# EFM32G290F128 register map
File version: 4.0.0
CPU: CM3 r2p0, little endian, MPU, no FPU, 3 interrupt priority bits
Registers are 32-bit, read-write, reset 0x0 unless marked. A register's access mark holds for its fields unless they carry their own. Offsets are from the block's base; [hi:lo] are bit positions; {n}, {i} and the like mark numbered series.

## ACMP0
Base 0x40001000
Same registers: ACMP1 0x40001400
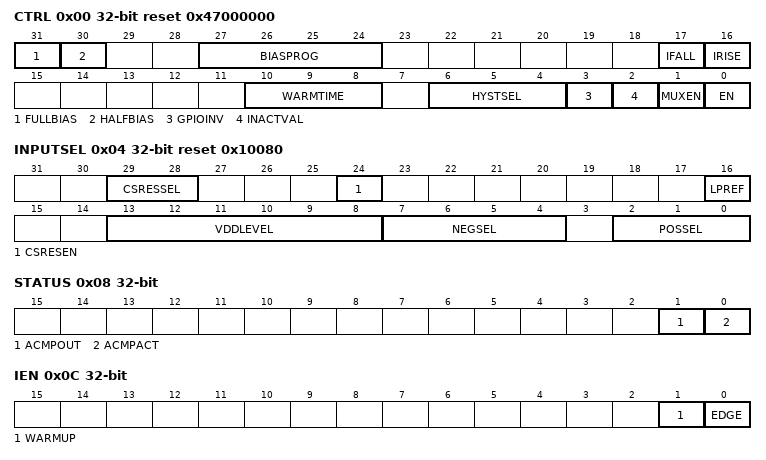
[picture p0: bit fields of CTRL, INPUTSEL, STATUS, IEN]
0x00 CTRL reset 0x47000000 — Control Register
  [31] FULLBIAS — Full Bias Current
  [30] HALFBIAS — Half Bias Current
  [27:24] BIASPROG — Bias Configuration
  [17] IFALL — Falling Edge Interrupt Sense
  [16] IRISE — Rising Edge Interrupt Sense
  [10:8] WARMTIME — Warm-up Time
    0=4CYCLES (4 HFPERCLK cycles.); 1=8CYCLES (8 HFPERCLK cycles.); 2=16CYCLES (16 HFPERCLK cycles.); 3=32CYCLES (32 HFPERCLK cycles.); 4=64CYCLES (64 HFPERCLK cycles.); 5=128CYCLES (128 HFPERCLK cycles.); 6=256CYCLES (256 HFPERCLK cycles.); 7=512CYCLES (512 HFPERCLK cycles.)
  [6:4] HYSTSEL — Hysteresis Select
    0=HYST0 (No hysteresis.); 1=HYST1 (~15 mV hysteresis.); 2=HYST2 (~22 mV hysteresis.); 3=HYST3 (~29 mV hysteresis.); 4=HYST4 (~36 mV hysteresis.); 5=HYST5 (~43 mV hysteresis.); 6=HYST6 (~50 mV hysteresis.); 7=HYST7 (~57 mV hysteresis.)
  [3] GPIOINV — Comparator GPIO Output Invert
  [2] INACTVAL — Inactive Value
  [1] MUXEN — Input Mux Enable
  [0] EN — Analog Comparator Enable
0x04 INPUTSEL reset 0x10080 — Input Selection Register
  [29:28] CSRESSEL — Capacitive Sense Mode Internal Resistor Select
    {v}=RES{v} (Internal capacitive sense resistor value {v}.) (v=0..3)
  [24] CSRESEN — Capacitive Sense Mode Internal Resistor Enable
  [16] LPREF — Low Power Reference Mode
  [13:8] VDDLEVEL — VDD Reference Level
  [7:4] NEGSEL — Negative Input Select
    {v}=CH{v} (Channel {v} as negative input.) (v=0..7); 8=1V25 (1.25 V as negative input.); 9=2V5 (2.5 V as negative input.); 10=VDD (Scaled VDD as negative input.); 11=CAPSENSE (Capacitive sense mode.)
  [2:0] POSSEL — Positive Input Select
    {v}=CH{v} (Channel {v} as positive input.) (v=0..7)
0x08 STATUS ro
  [1] ACMPOUT — Analog Comparator Output
  [0] ACMPACT — Analog Comparator Active
0x0C IEN — Interrupt Enable Register
  [1] WARMUP — Warm-up Interrupt Enable
  [0] EDGE — Edge Trigger Interrupt Enable
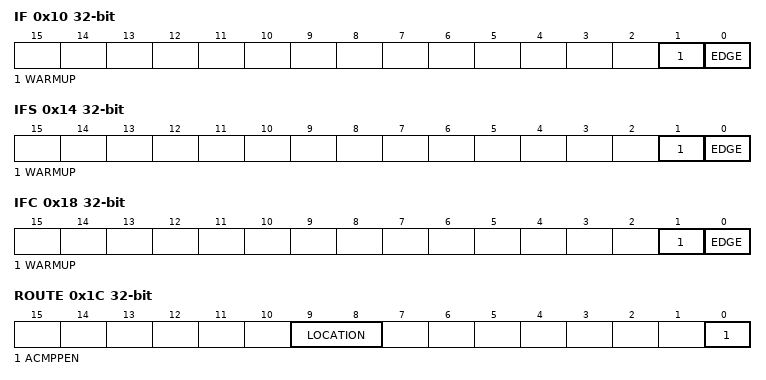
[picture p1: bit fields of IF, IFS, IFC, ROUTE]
0x10 IF ro — Interrupt Flag Register
  [1] WARMUP — Warm-up Interrupt Flag
  [0] EDGE — Edge Triggered Interrupt Flag
0x14 IFS wo — Interrupt Flag Set Register
  [1] WARMUP — Warm-up Interrupt Flag Set
  [0] EDGE — Edge Triggered Interrupt Flag Set
0x18 IFC wo — Interrupt Flag Clear Register
  [1] WARMUP — Warm-up Interrupt Flag Clear
  [0] EDGE — Edge Triggered Interrupt Flag Clear
0x1C ROUTE — I/O Routing Register
  [9:8] LOCATION — I/O Location
    0=LOC0 (Location 0); 1=LOC1 (Location 1)
  [0] ACMPPEN — ACMP Output Pin Enable

## PRS
Base 0x400CC000
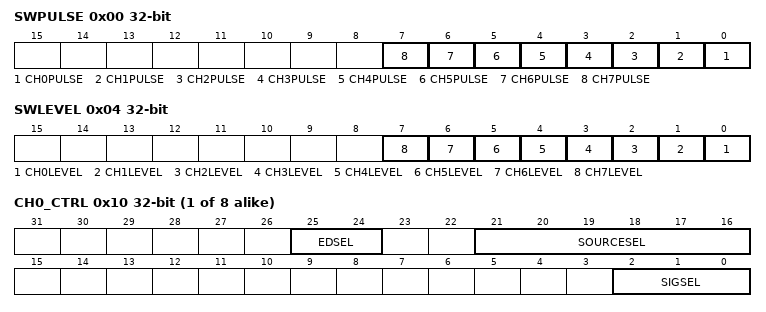
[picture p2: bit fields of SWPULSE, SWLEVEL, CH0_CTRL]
0x00 SWPULSE wo — Software Pulse Register
  [n] CH{n}PULSE (n=0..7) — Channel {n} Pulse Generation
0x04 SWLEVEL — Software Level Register
  [n] CH{n}LEVEL (n=0..7) — Channel {n} Software Level
{0x10+4i} CH{i}_CTRL (i=0..7) — Channel Control Register
  [25:24] EDSEL — Edge Detect Select
    0=OFF (Signal is left as it is); 1=POSEDGE (A one HFPERCLK cycle pulse is generated for every positive edge of the incoming signal); 2=NEGEDGE (A one HFPERCLK clock cycle pulse is generated for every negative edge of the incoming signal); 3=BOTHEDGES (A one HFPERCLK clock cycle pulse is generated for every edge of the incoming signal)
  [21:16] SOURCESEL — Source Select
    0=NONE (No source selected); 1=VCMP (Voltage Comparator); 2=ACMP0 (Analog Comparator 0); 3=ACMP1 (Analog Comparator 1); 6=DAC0 (Digital to Analog Converter 0); 8=ADC0 (Analog to Digital Converter 0); 16=USART0 (Universal Synchronous/Asynchronous Receiver/Transmitter 0); 17=USART1 (Universal Synchronous/Asynchronous Receiver/Transmitter 1); 18=USART2 (Universal Synchronous/Asynchronous Receiver/Transmitter 2); 28=TIMER0; 29=TIMER1; 30=TIMER2; 40=RTC (Real-Time Counter); 41=UART0 (Universal Asynchronous Receiver/Transmitter 0); 48=GPIOL (General purpose Input/Output); 49=GPIOH (General purpose Input/Output)
  [2:0] SIGSEL — Signal Select

## Notices in the file
# License
Copyright 2021 Silicon Laboratories Inc. www.silabs.com
SPDX-License-Identifier: Zlib
The licensor of this software is Silicon Laboratories Inc.
This software is provided 'as-is', without any express or implied
warranty. In no event will the authors be held liable for any damages
arising from the use of this software.
Permission is granted to anyone to use this software for any purpose,
including commercial applications, and to alter it and redistribute it
freely, subject to the following restrictions:
1. The origin of this software must not be misrepresented; you must not
claim that you wrote the original software. If you use this software
in a product, an acknowledgment in the product documentation would be
appreciated but is not required.
2. Altered source versions must be plainly marked as such, and must not be
misrepresented as being the original software.
3. This notice may not be removed or altered from any source distribution.
